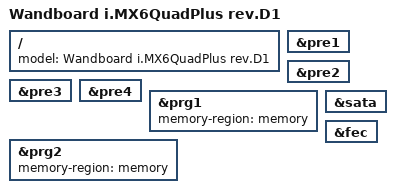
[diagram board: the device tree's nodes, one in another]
/*
 * Copyright 2013-2017 Freescale Semiconductor, Inc.
 * Copyright 2017 Wandboard, Org.
 *
 * Author: Fabio Estevam <fabio.estevam@freescale.com>
 *         Richard Hu <richard.hu@technexion.com>
 *
 * This program is free software; you can redistribute it and/or modify
 * it under the terms of the GNU General Public License version 2 as
 * published by the Free Software Foundation.
 *
 */

#include "imx6q-wandboard-revd1.dts"
#include "imx6qp.dtsi"

/ {
	model = "Wandboard i.MX6QuadPlus rev.D1";
};

&pre1 {
	status = "okay";
};

&pre2 {
	status = "okay";
};

&pre3 {
	status = "okay";
};

&pre4 {
	status = "okay";
};

&prg1 {
	memory-region = <&memory>;
	status = "okay";
};

&prg2 {
	memory-region = <&memory>;
	status = "okay";
};

&sata {
	status = "okay";
};

&fec {
    /delete-property/ phy-reset-gpios;
};
